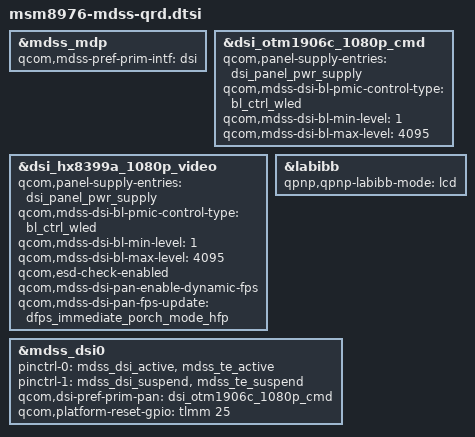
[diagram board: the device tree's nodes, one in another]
// SPDX-License-Identifier: GPL-2.0
// Copyright (c) 2015, The Linux Foundation. All rights reserved.
// Copyright (c) 2023, Benarji Anand <benarji385@gmail.com>

&mdss_mdp {
	qcom,mdss-pref-prim-intf = "dsi";
};

&dsi_otm1906c_1080p_cmd {
	qcom,panel-supply-entries = <&dsi_panel_pwr_supply>;
	qcom,mdss-dsi-bl-pmic-control-type = "bl_ctrl_wled";
	qcom,mdss-dsi-bl-min-level = <1>;
	qcom,mdss-dsi-bl-max-level = <4095>;
};

&dsi_hx8399a_1080p_video {
	qcom,panel-supply-entries = <&dsi_panel_pwr_supply>;
	qcom,mdss-dsi-bl-pmic-control-type = "bl_ctrl_wled";
	qcom,mdss-dsi-bl-min-level = <1>;
	qcom,mdss-dsi-bl-max-level = <4095>;
	qcom,esd-check-enabled;
	qcom,mdss-dsi-pan-enable-dynamic-fps;
	qcom,mdss-dsi-pan-fps-update = "dfps_immediate_porch_mode_hfp";
};

&labibb {
	status = "ok";
	qpnp,qpnp-labibb-mode = "lcd";
};

&mdss_dsi0 {
	pinctrl-names = "mdss_default", "mdss_sleep";
	pinctrl-0 = <&mdss_dsi_active &mdss_te_active>;
	pinctrl-1 = <&mdss_dsi_suspend &mdss_te_suspend>;
	qcom,dsi-pref-prim-pan = <&dsi_otm1906c_1080p_cmd>;

	qcom,platform-reset-gpio = <&tlmm 25 0>;
};
